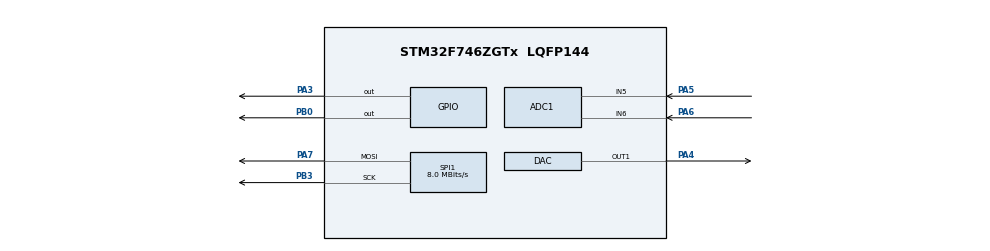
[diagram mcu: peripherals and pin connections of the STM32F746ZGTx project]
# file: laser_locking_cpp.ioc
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ADC1.Channel-0\#ChannelRegularConversion=ADC_CHANNEL_6
ADC1.Channel-1\#ChannelRegularConversion=ADC_CHANNEL_5
ADC1.ClockPrescaler=ADC_CLOCK_SYNC_PCLK_DIV6
ADC1.ContinuousConvMode=ENABLE
ADC1.DMAContinuousRequests=ENABLE
ADC1.NbrOfConversion=2
ADC1.NbrOfConversionFlag=1
ADC1.Rank-0\#ChannelRegularConversion=1
ADC1.Rank-1\#ChannelRegularConversion=2
ADC1.SamplingTime-0\#ChannelRegularConversion=ADC_SAMPLETIME_144CYCLES
ADC1.SamplingTime-1\#ChannelRegularConversion=ADC_SAMPLETIME_144CYCLES
ADC1.ScanConvMode=ADC_SCAN_ENABLE
ADC1.master=1
Dma.ADC1.0.Direction=DMA_PERIPH_TO_MEMORY
Dma.ADC1.0.FIFOMode=DMA_FIFOMODE_DISABLE
Dma.ADC1.0.Instance=DMA2_Stream0
Dma.ADC1.0.MemDataAlignment=DMA_MDATAALIGN_HALFWORD
Dma.ADC1.0.MemInc=DMA_MINC_ENABLE
Dma.ADC1.0.Mode=DMA_CIRCULAR
Dma.ADC1.0.PeriphDataAlignment=DMA_PDATAALIGN_HALFWORD
Dma.ADC1.0.PeriphInc=DMA_PINC_DISABLE
Dma.ADC1.0.Priority=DMA_PRIORITY_LOW
Dma.Request0=ADC1
Mcu.Family=STM32F7
Mcu.Name=STM32F746ZGTx
Mcu.Package=LQFP144
NVIC.DMA2_Stream0_IRQn=true\:0\:0\:false\:false\:true\:false\:true\:true
NVIC.PriorityGroup=NVIC_PRIORITYGROUP_4
PA3.Signal=GPIO_Output
PA4.Signal=COMP_DAC1_group
PA5.Signal=ADCx_IN5
PA6.Signal=ADCx_IN6
PA7.Mode=TX_Only_Simplex_Unidirect_Master
PA7.Signal=SPI1_MOSI
PB0.Signal=GPIO_Output
PB3.Mode=TX_Only_Simplex_Unidirect_Master
PB3.Signal=SPI1_SCK
ProjectManager.HeapSize=0x200
ProjectManager.StackSize=0x400
ProjectManager.TargetToolchain=STM32CubeIDE
RCC.HSE_VALUE=25000000
RCC.HSI_VALUE=16000000
RCC.LSE_VALUE=32768
RCC.USBFreq_Value=96000000
RCC.VCOOutputFreq_Value=192000000
SH.ADCx_IN5.0=ADC1_IN5,IN5
SH.ADCx_IN6.0=ADC1_IN6,IN6
SH.COMP_DAC1_group.0=DAC_OUT1,DAC_OUT1
SPI1.CLKPhase=SPI_PHASE_2EDGE
SPI1.CalculateBaudRate=8.0 MBits/s
SPI1.DataSize=SPI_DATASIZE_16BIT
SPI1.Direction=SPI_DIRECTION_2LINES
SPI1.Mode=SPI_MODE_MASTER
SPI1.VirtualType=VM_MASTER
board=custom

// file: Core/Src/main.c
/* USER CODE BEGIN Header */
/**
  ******************************************************************************
  * @file           : main.c
  * @brief          : Main program body
  ******************************************************************************
  * @attention
  *
  * <h2><center>&copy; Copyright (c) 2023 STMicroelectronics.
  * All rights reserved.</center></h2>
  *
  * This software component is licensed by ST under BSD 3-Clause license,
  * the "License"; You may not use this file except in compliance with the
  * License. You may obtain a copy of the License at:
  *                        opensource.org/licenses/BSD-3-Clause
  *
  ******************************************************************************
  */
/* USER CODE END Header */
#include "main.h"
#include "adc.h"
#include "dac.h"
#include "dma.h"
#include "spi.h"
#include "gpio.h"

void SystemClock_Config(void);
/* USER CODE BEGIN PFP */
int alt_main();
/* USER CODE END PFP */

int main(void)
{

  /* MCU Configuration--------------------------------------------------------*/

  /* Reset of all peripherals, Initializes the Flash interface and the Systick. */
  HAL_Init();

  /* Configure the system clock */
  SystemClock_Config();

  /* Initialize all configured peripherals */
  MX_GPIO_Init();
  MX_DMA_Init();
  MX_ADC1_Init();
  MX_DAC_Init();
  MX_SPI1_Init();
  /* USER CODE BEGIN 2 */

  alt_main();
  /* USER CODE END 2 */

  /* Infinite loop */
  while (1)
  {

  }
}

void SystemClock_Config(void)
{
  RCC_OscInitTypeDef RCC_OscInitStruct = {0};
  RCC_ClkInitTypeDef RCC_ClkInitStruct = {0};

  /** Configure the main internal regulator output voltage
  */
  __HAL_RCC_PWR_CLK_ENABLE();
  __HAL_PWR_VOLTAGESCALING_CONFIG(PWR_REGULATOR_VOLTAGE_SCALE3);

  /** Initializes the RCC Oscillators according to the specified parameters
  * in the RCC_OscInitTypeDef structure.
  */
  RCC_OscInitStruct.OscillatorType = RCC_OSCILLATORTYPE_HSI;
  RCC_OscInitStruct.HSIState = RCC_HSI_ON;
  RCC_OscInitStruct.HSICalibrationValue = RCC_HSICALIBRATION_DEFAULT;
  RCC_OscInitStruct.PLL.PLLState = RCC_PLL_NONE;
  if (HAL_RCC_OscConfig(&RCC_OscInitStruct) != HAL_OK)
  {
    Error_Handler();
  }

  /** Initializes the CPU, AHB and APB buses clocks
  */
  RCC_ClkInitStruct.ClockType = RCC_CLOCKTYPE_HCLK|RCC_CLOCKTYPE_SYSCLK
                              |RCC_CLOCKTYPE_PCLK1|RCC_CLOCKTYPE_PCLK2;
  RCC_ClkInitStruct.SYSCLKSource = RCC_SYSCLKSOURCE_HSI;
  RCC_ClkInitStruct.AHBCLKDivider = RCC_SYSCLK_DIV1;
  RCC_ClkInitStruct.APB1CLKDivider = RCC_HCLK_DIV1;
  RCC_ClkInitStruct.APB2CLKDivider = RCC_HCLK_DIV1;

  if (HAL_RCC_ClockConfig(&RCC_ClkInitStruct, FLASH_LATENCY_0) != HAL_OK)
  {
    Error_Handler();
  }
}

void Error_Handler(void)
{
}
